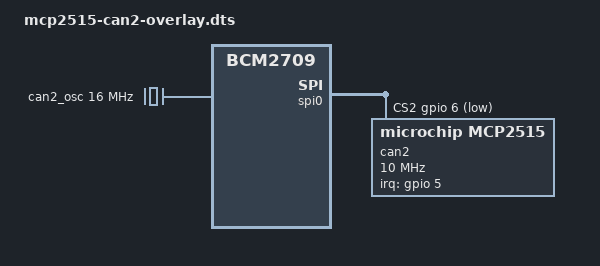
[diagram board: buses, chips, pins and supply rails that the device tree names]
/*
 * Device tree overlay for mcp251x/can2 on spi0.2
 */

/dts-v1/;
/plugin/;

/ {
    compatible = "brcm,bcm2835", "brcm,bcm2836", "brcm,bcm2708", "brcm,bcm2709";
    /* disable spi-dev for spi0.2 */
    fragment@0 {
        target = <&spi0>;
        __overlay__ {
            status = "okay";
        };
    };

    fragment@1 {
      target = <&spi0_cs_pins>;
      cs_pins: __overlay__ {
         brcm,pins = <8 7 6>;
      };
    };

    /* the interrupt pin of the can-controller */
    fragment@2 {
        target = <&gpio>;
        __overlay__ {
            can2_pins: can2_pins {
                brcm,pins = <5>;
                brcm,function = <0>; /* input */
            };
        };
    };

    /* the clock/oscillator of the can-controller */
    fragment@3 {
        target-path = "/clocks";
        __overlay__ {
            /* external oscillator of mcp2515 on spi0.2 */
            can2_osc: can2_osc {
                compatible = "fixed-clock";
                #clock-cells = <0>;
                clock-frequency  = <16000000>;
            };
        };
    };

    /* the spi config of the can-controller itself binding everything together */
    fragment@4 {
        target = <&spi0>;
        spi: __overlay__ {
            /* needed to avoid dtc warning */
            #address-cells = <1>;
            #size-cells = <0>;

            cs-gpios = <&gpio 8 1>, <&gpio 7 1>, <&gpio 6 1>;

            can2: mcp2515@2 {
                reg = <2>;
                compatible = "microchip,mcp2515";
                pinctrl-names = "default";
                pinctrl-0 = <&can2_pins>;
                spi-max-frequency = <10000000>;
                interrupt-parent = <&gpio>;
                interrupts = <5 8>; /* IRQF_TRIGGER_LOW */
                clocks = <&can2_osc>;
            };
        };
    };
    __overrides__ {
        oscillator = <&can2_osc>,"clock-frequency:0";
        spimaxfrequency = <&can2>,"spi-max-frequency:0";
        interrupt = <&can2_pins>,"brcm,pins:0",<&can2>,"interrupts:0";
        cs2 = <&cs_pins>,"brcm,pins:8", <&spi>,"cs-gpios:28";
    };
};
